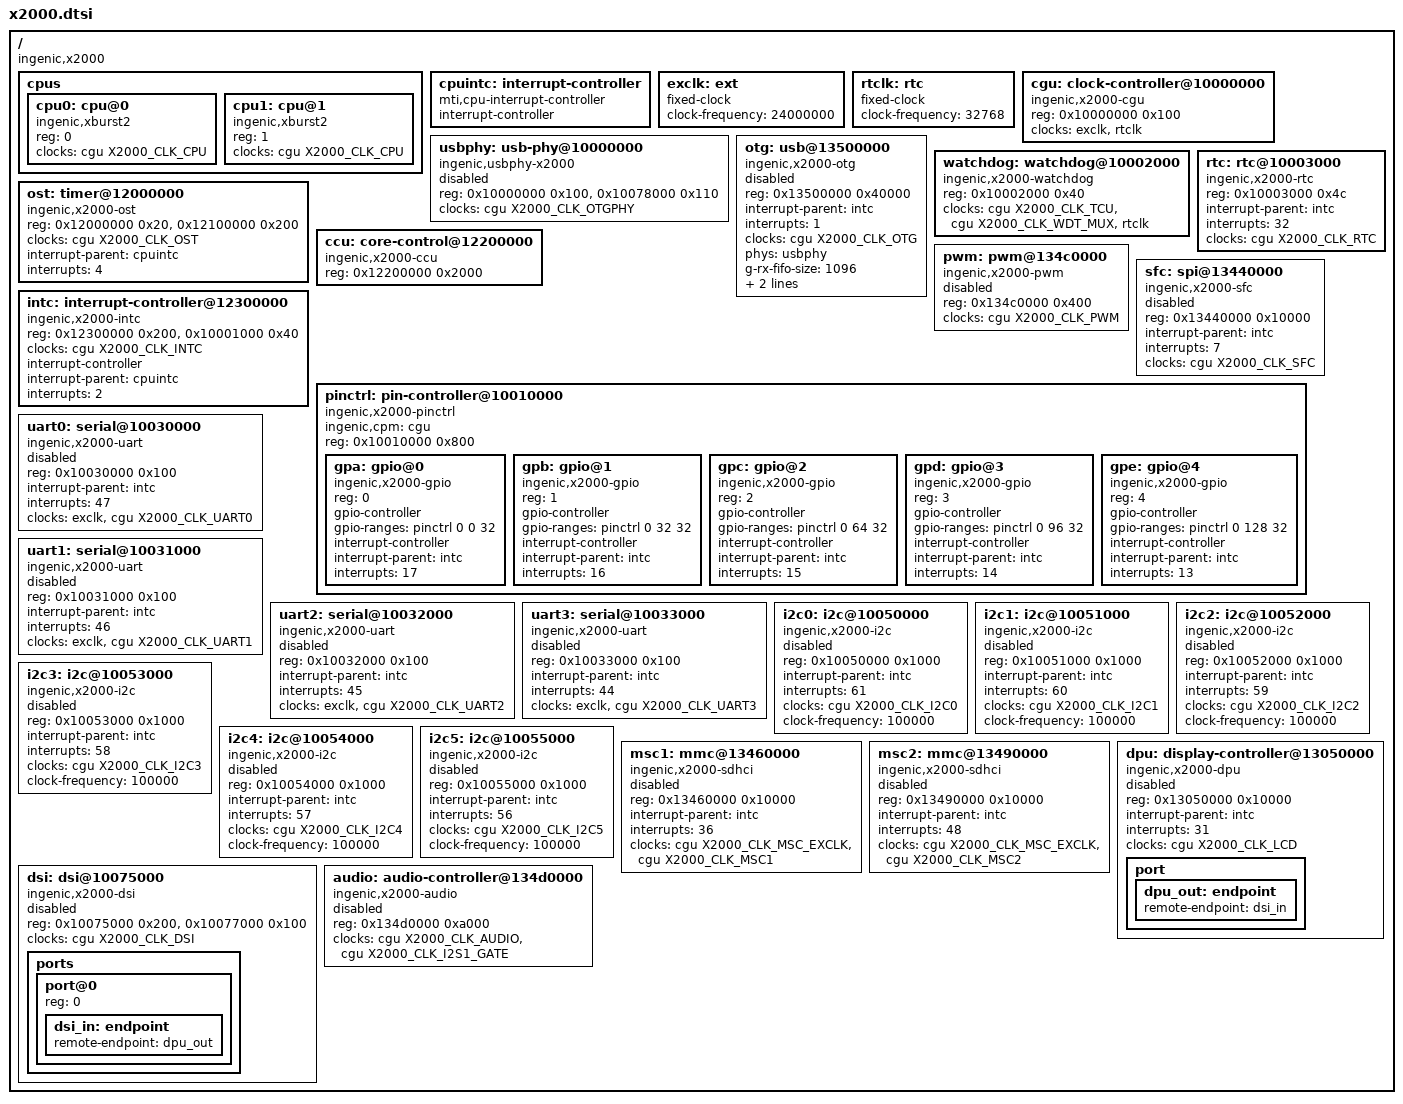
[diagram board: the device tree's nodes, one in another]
// SPDX-License-Identifier: GPL-2.0
/*
 * Ingenic X2000 SoC.
 *
 * Based on the X2000 device tree by Zhou Yanjie in the Ingenic-community
 * kernel, with the interrupt controller, OST and CCU as the vendor kernel
 * uses them.
 */
#include <dt-bindings/clock/ingenic,x2000-cgu.h>

/ {
	#address-cells = <1>;
	#size-cells = <1>;
	compatible = "ingenic,x2000";

	cpus {
		#address-cells = <1>;
		#size-cells = <0>;

		cpu0: cpu@0 {
			device_type = "cpu";
			compatible = "ingenic,xburst2";
			reg = <0>;
			clocks = <&cgu X2000_CLK_CPU>;
			clock-names = "cpu";
		};

		cpu1: cpu@1 {
			device_type = "cpu";
			compatible = "ingenic,xburst2";
			reg = <1>;
			clocks = <&cgu X2000_CLK_CPU>;
			clock-names = "cpu";
		};
	};

	cpuintc: interrupt-controller {
		compatible = "mti,cpu-interrupt-controller";
		#address-cells = <0>;
		#interrupt-cells = <1>;
		interrupt-controller;
	};

	exclk: ext {
		compatible = "fixed-clock";
		#clock-cells = <0>;
		clock-frequency = <24000000>;
	};

	rtclk: rtc {
		compatible = "fixed-clock";
		#clock-cells = <0>;
		clock-frequency = <32768>;
	};

	cgu: clock-controller@10000000 {
		compatible = "ingenic,x2000-cgu";
		#power-domain-cells = <1>;
		reg = <0x10000000 0x100>;
		#clock-cells = <1>;
		clocks = <&exclk>, <&rtclk>;
		clock-names = "ext", "rtc";
	};

	usbphy: usb-phy@10000000 {
		compatible = "ingenic,usbphy-x2000";
		reg = <0x10000000 0x100>, <0x10078000 0x110>;
		clocks = <&cgu X2000_CLK_OTGPHY>;
		#phy-cells = <0>;
		status = "disabled";
	};

	otg: usb@13500000 {
		compatible = "ingenic,x2000-otg";
		reg = <0x13500000 0x40000>;
		interrupt-parent = <&intc>;
		interrupts = <1>;
		clocks = <&cgu X2000_CLK_OTG>;
		clock-names = "otg";
		phys = <&usbphy>;
		phy-names = "usb2-phy";
		g-rx-fifo-size = <1096>;
		g-np-tx-fifo-size = <512>;
		g-tx-fifo-size = <16 16 16 128 256 256 512 768>;
		status = "disabled";
	};

	watchdog: watchdog@10002000 {
		compatible = "ingenic,x2000-watchdog";
		reg = <0x10002000 0x40>;
		/* OPCR[2] watchdog mux; RTC seconds retain their independent rtclk. */
		clocks = <&cgu X2000_CLK_TCU>, <&cgu X2000_CLK_WDT_MUX>, <&rtclk>;
		clock-names = "tcu", "rtc", "sleep";
	};

	rtc: rtc@10003000 {
		compatible = "ingenic,x2000-rtc";
		reg = <0x10003000 0x4c>;
		interrupt-parent = <&intc>;
		interrupts = <32>;
		clocks = <&cgu X2000_CLK_RTC>;
		clock-names = "rtc";
	};

	ost: timer@12000000 {
		compatible = "ingenic,x2000-ost";
		/* global 64-bit counter, then the per-core timers */
		reg = <0x12000000 0x20>, <0x12100000 0x200>;
		clocks = <&cgu X2000_CLK_OST>;
		clock-names = "ost";
		interrupt-parent = <&cpuintc>;
		interrupts = <4>;
	};

	ccu: core-control@12200000 {
		compatible = "ingenic,x2000-ccu";
		reg = <0x12200000 0x2000>;
	};

	pwm: pwm@134c0000 {
		compatible = "ingenic,x2000-pwm";
		reg = <0x134c0000 0x400>;
		clocks = <&cgu X2000_CLK_PWM>;
		#pwm-cells = <3>;
		status = "disabled";
	};

	sfc: spi@13440000 {
		compatible = "ingenic,x2000-sfc";
		reg = <0x13440000 0x10000>;
		interrupt-parent = <&intc>;
		interrupts = <7>;
		clocks = <&cgu X2000_CLK_SFC>;
		#address-cells = <1>;
		#size-cells = <0>;
		status = "disabled";
	};

	intc: interrupt-controller@12300000 {
		compatible = "ingenic,x2000-intc";
		/* Per-core routing and separate clock-gated system-wake bank. */
		reg = <0x12300000 0x200>, <0x10001000 0x40>;
		reg-names = "core", "wake";
		clocks = <&cgu X2000_CLK_INTC>;
		clock-names = "wake";
		interrupt-controller;
		#interrupt-cells = <1>;
		interrupt-parent = <&cpuintc>;
		interrupts = <2>;
	};

	pinctrl: pin-controller@10010000 {
		compatible = "ingenic,x2000-pinctrl";
		ingenic,cpm = <&cgu>;
		reg = <0x10010000 0x800>;
		#address-cells = <1>;
		#size-cells = <0>;

		gpa: gpio@0 {
			compatible = "ingenic,x2000-gpio";
			reg = <0>;
			gpio-controller;
			gpio-ranges = <&pinctrl 0 0 32>;
			#gpio-cells = <2>;
			interrupt-controller;
			#interrupt-cells = <2>;
			interrupt-parent = <&intc>;
			interrupts = <17>;
		};

		gpb: gpio@1 {
			compatible = "ingenic,x2000-gpio";
			reg = <1>;
			gpio-controller;
			gpio-ranges = <&pinctrl 0 32 32>;
			#gpio-cells = <2>;
			interrupt-controller;
			#interrupt-cells = <2>;
			interrupt-parent = <&intc>;
			interrupts = <16>;
		};

		gpc: gpio@2 {
			compatible = "ingenic,x2000-gpio";
			reg = <2>;
			gpio-controller;
			gpio-ranges = <&pinctrl 0 64 32>;
			#gpio-cells = <2>;
			interrupt-controller;
			#interrupt-cells = <2>;
			interrupt-parent = <&intc>;
			interrupts = <15>;
		};

		gpd: gpio@3 {
			compatible = "ingenic,x2000-gpio";
			reg = <3>;
			gpio-controller;
			gpio-ranges = <&pinctrl 0 96 32>;
			#gpio-cells = <2>;
			interrupt-controller;
			#interrupt-cells = <2>;
			interrupt-parent = <&intc>;
			interrupts = <14>;
		};

		gpe: gpio@4 {
			compatible = "ingenic,x2000-gpio";
			reg = <4>;
			gpio-controller;
			gpio-ranges = <&pinctrl 0 128 32>;
			#gpio-cells = <2>;
			interrupt-controller;
			#interrupt-cells = <2>;
			interrupt-parent = <&intc>;
			interrupts = <13>;
		};
	};

	uart0: serial@10030000 {
		compatible = "ingenic,x2000-uart", "ingenic,x1000-uart";
		reg = <0x10030000 0x100>;
		interrupt-parent = <&intc>;
		interrupts = <47>;
		clocks = <&exclk>, <&cgu X2000_CLK_UART0>;
		clock-names = "baud", "module";
		status = "disabled";
	};

	uart1: serial@10031000 {
		compatible = "ingenic,x2000-uart", "ingenic,x1000-uart";
		reg = <0x10031000 0x100>;
		interrupt-parent = <&intc>;
		interrupts = <46>;
		clocks = <&exclk>, <&cgu X2000_CLK_UART1>;
		clock-names = "baud", "module";
		status = "disabled";
	};

	uart2: serial@10032000 {
		compatible = "ingenic,x2000-uart", "ingenic,x1000-uart";
		reg = <0x10032000 0x100>;
		interrupt-parent = <&intc>;
		interrupts = <45>;
		clocks = <&exclk>, <&cgu X2000_CLK_UART2>;
		clock-names = "baud", "module";
		status = "disabled";
	};

	uart3: serial@10033000 {
		compatible = "ingenic,x2000-uart", "ingenic,x1000-uart";
		reg = <0x10033000 0x100>;
		interrupt-parent = <&intc>;
		interrupts = <44>;
		clocks = <&exclk>, <&cgu X2000_CLK_UART3>;
		clock-names = "baud", "module";
		status = "disabled";
	};

	i2c0: i2c@10050000 {
		compatible = "ingenic,x2000-i2c", "ingenic,x1000-i2c";
		reg = <0x10050000 0x1000>;
		interrupt-parent = <&intc>;
		interrupts = <61>;
		clocks = <&cgu X2000_CLK_I2C0>;
		clock-frequency = <100000>;
		#address-cells = <1>;
		#size-cells = <0>;
		status = "disabled";
	};

	i2c1: i2c@10051000 {
		compatible = "ingenic,x2000-i2c", "ingenic,x1000-i2c";
		reg = <0x10051000 0x1000>;
		interrupt-parent = <&intc>;
		interrupts = <60>;
		clocks = <&cgu X2000_CLK_I2C1>;
		clock-frequency = <100000>;
		#address-cells = <1>;
		#size-cells = <0>;
		status = "disabled";
	};

	i2c2: i2c@10052000 {
		compatible = "ingenic,x2000-i2c", "ingenic,x1000-i2c";
		reg = <0x10052000 0x1000>;
		interrupt-parent = <&intc>;
		interrupts = <59>;
		clocks = <&cgu X2000_CLK_I2C2>;
		clock-frequency = <100000>;
		#address-cells = <1>;
		#size-cells = <0>;
		status = "disabled";
	};

	i2c3: i2c@10053000 {
		compatible = "ingenic,x2000-i2c", "ingenic,x1000-i2c";
		reg = <0x10053000 0x1000>;
		interrupt-parent = <&intc>;
		interrupts = <58>;
		clocks = <&cgu X2000_CLK_I2C3>;
		clock-frequency = <100000>;
		#address-cells = <1>;
		#size-cells = <0>;
		status = "disabled";
	};

	i2c4: i2c@10054000 {
		compatible = "ingenic,x2000-i2c", "ingenic,x1000-i2c";
		reg = <0x10054000 0x1000>;
		interrupt-parent = <&intc>;
		interrupts = <57>;
		clocks = <&cgu X2000_CLK_I2C4>;
		clock-frequency = <100000>;
		#address-cells = <1>;
		#size-cells = <0>;
		status = "disabled";
	};

	i2c5: i2c@10055000 {
		compatible = "ingenic,x2000-i2c", "ingenic,x1000-i2c";
		reg = <0x10055000 0x1000>;
		interrupt-parent = <&intc>;
		interrupts = <56>;
		clocks = <&cgu X2000_CLK_I2C5>;
		clock-frequency = <100000>;
		#address-cells = <1>;
		#size-cells = <0>;
		status = "disabled";
	};

	msc1: mmc@13460000 {
		compatible = "ingenic,x2000-sdhci";
		reg = <0x13460000 0x10000>;
		interrupt-parent = <&intc>;
		interrupts = <36>;
		clocks = <&cgu X2000_CLK_MSC_EXCLK>, <&cgu X2000_CLK_MSC1>;
		clock-names = "ext", "sdhci";
		status = "disabled";
	};

	msc2: mmc@13490000 {
		compatible = "ingenic,x2000-sdhci";
		reg = <0x13490000 0x10000>;
		interrupt-parent = <&intc>;
		interrupts = <48>;
		clocks = <&cgu X2000_CLK_MSC_EXCLK>, <&cgu X2000_CLK_MSC2>;
		clock-names = "ext", "sdhci";
		status = "disabled";
	};
};

/ {
	dpu: display-controller@13050000 {
		compatible = "ingenic,x2000-dpu";
		reg = <0x13050000 0x10000>;
		interrupt-parent = <&intc>;
		interrupts = <31>;
		clocks = <&cgu X2000_CLK_LCD>;
		clock-names = "lcd";
		status = "disabled";
		port { dpu_out: endpoint { remote-endpoint = <&dsi_in>; }; };
	};
	dsi: dsi@10075000 {
		compatible = "ingenic,x2000-dsi";
		reg = <0x10075000 0x200>, <0x10077000 0x100>;
		clocks = <&cgu X2000_CLK_DSI>;
		clock-names = "pclk";
		#address-cells = <1>;
		#size-cells = <0>;
		status = "disabled";
		ports {
			#address-cells = <1>;
			#size-cells = <0>;
			port@0 { reg = <0>; dsi_in: endpoint { remote-endpoint = <&dpu_out>; }; };
		};
	};
};

/ {
	audio: audio-controller@134d0000 {
		compatible = "ingenic,x2000-audio";
		reg = <0x134d0000 0xa000>;
		clocks = <&cgu X2000_CLK_AUDIO>, <&cgu X2000_CLK_I2S1_GATE>;
		clock-names = "audio", "i2s1";
		#sound-dai-cells = <0>;
		status = "disabled";
	};
};
